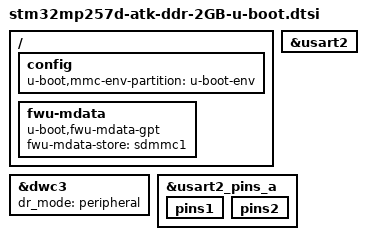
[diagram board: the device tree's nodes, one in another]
#include "stm32mp25-u-boot.dtsi"

/ {
	config {
		u-boot,mmc-env-partition = "u-boot-env";
	};

	fwu-mdata {
		compatible = "u-boot,fwu-mdata-gpt";
		fwu-mdata-store = <&sdmmc1>;
	};
};

&dwc3 {
	dr_mode = "peripheral";
	/delete-node/ port;
};

&usart2 {
	bootph-all;
};

&usart2_pins_a {
	bootph-all;
	pins1 {
		bootph-all;
	};
	pins2 {
		bootph-all;
	};
};
